# MKW31Z4 register map
Vendor: Freescale Semiconductor, Inc.; Series: Kinetis_W; File version: 1.6
CPU: CM0PLUS r0p0, little endian, no MPU, no FPU, VTOR, 2 interrupt priority bits
Registers are 16-bit, read-write, no defined reset value unless marked. A register's access mark holds for its fields unless they carry their own. Offsets are from the block's base; [hi:lo] are bit positions; {n}, {i} and the like mark numbered series.

## RCM — Reset Control Module
Base 0x4007F000; register names take the prefix RCM_
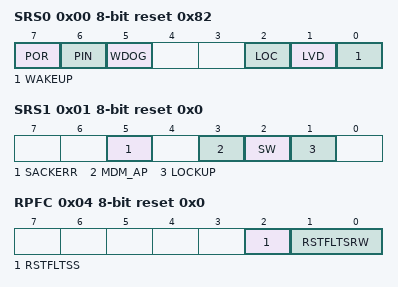
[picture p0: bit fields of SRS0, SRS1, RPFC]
0x00 SRS0 8-bit ro reset 0x82 — System Reset Status Register 0
  [7] POR — Power-On Reset
    0=Reset not caused by POR; 1=Reset caused by POR
  [6] PIN — External Reset Pin
    0=Reset not caused by external reset pin; 1=Reset caused by external reset pin
  [5] WDOG — Watchdog
    0=Reset not caused by watchdog timeout; 1=Reset caused by watchdog timeout
  [2] LOC — Loss-of-Clock Reset
    0=Reset not caused by a loss of external clock; 1=Reset caused by a loss of external clock
  [1] LVD — Low-Voltage Detect Reset
    0=Reset not caused by LVD trip or POR; 1=Reset caused by LVD trip or POR
  [0] WAKEUP — Low Leakage Wakeup Reset
    0=Reset not caused by LLWU module wakeup source; 1=Reset caused by LLWU module wakeup source
0x01 SRS1 8-bit ro reset 0x0 — System Reset Status Register 1
  [5] SACKERR — Stop Mode Acknowledge Error Reset
    0=Reset not caused by peripheral failure to acknowledge attempt to enter stop mode; 1=Reset caused by peripheral failure to acknowledge attempt to enter stop mode
  [3] MDM_AP — MDM-AP System Reset Request
    0=Reset not caused by host debugger system setting of the System Reset Request bit; 1=Reset caused by host debugger system setting of the System Reset Request bit
  [2] SW — Software
    0=Reset not caused by software setting of SYSRESETREQ bit; 1=Reset caused by software setting of SYSRESETREQ bit
  [1] LOCKUP — Core Lockup
    0=Reset not caused by core LOCKUP event; 1=Reset caused by core LOCKUP event
0x04 RPFC 8-bit reset 0x0 — Reset Pin Filter Control register
  [2] RSTFLTSS — Reset Pin Filter Select in Stop Mode
    0=All filtering disabled; 1=LPO clock filter enabled
  [1:0] RSTFLTSRW — Reset Pin Filter Select in Run and Wait Modes
    0=All filtering disabled; 1=Bus clock filter enabled for normal operation; 2=LPO clock filter enabled for normal operation
0x05 RPFW 8-bit reset 0x0 — Reset Pin Filter Width register
  [4:0] RSTFLTSEL — Reset Pin Filter Bus Clock Select
    {v}=Bus clock filter count is {v+1} (v=0..31)

## GPIOA — General Purpose Input/Output
Base 0x400FF000; register names take the prefix GPIOA_
0x00 PDOR 32-bit reset 0x0 — Port Data Output Register
  [31:0] PDO — Port Data Output
    0=Logic level 0 is driven on pin, provided pin is configured for general-purpose output; 1=Logic level 1 is driven on pin, provided pin is configured for general-purpose output
0x04 PSOR 32-bit wo reset 0x0 — Port Set Output Register
  [31:0] PTSO — Port Set Output
    0=Corresponding bit in PDORn does not change; 1=Corresponding bit in PDORn is set to logic 1
0x08 PCOR 32-bit wo reset 0x0 — Port Clear Output Register
  [31:0] PTCO — Port Clear Output
    0=Corresponding bit in PDORn does not change; 1=Corresponding bit in PDORn is cleared to logic 0
0x0C PTOR 32-bit wo reset 0x0 — Port Toggle Output Register
  [31:0] PTTO — Port Toggle Output
    0=Corresponding bit in PDORn does not change; 1=Corresponding bit in PDORn is set to the inverse of its existing logic state
0x10 PDIR 32-bit ro reset 0x0 — Port Data Input Register
  [31:0] PDI — Port Data Input
    0=Pin logic level is logic 0, or is not configured for use by digital function; 1=Pin logic level is logic 1
0x14 PDDR 32-bit reset 0x0 — Port Data Direction Register
  [31:0] PDD — Port Data Direction
    0=Pin is configured as general-purpose input, for the GPIO function; 1=Pin is configured as general-purpose output, for the GPIO function

## GPIOB — General Purpose Input/Output
Base 0x400FF040; register names take the prefix GPIOB_
Registers as GPIOA.

## GPIOC — General Purpose Input/Output
Base 0x400FF080; register names take the prefix GPIOC_
Registers as GPIOA.

## FGPIOA — General Purpose Input/Output
Base 0xF8000000; register names take the prefix FGPIOA_
Registers as GPIOA.

## FGPIOB — General Purpose Input/Output
Base 0xF8000040; register names take the prefix FGPIOB_
Registers as GPIOA.

## FGPIOC — General Purpose Input/Output
Base 0xF8000080; register names take the prefix FGPIOC_
Registers as GPIOA.

## Notices in the file
Redistribution and use in source and binary forms, with or without modification,
are permitted provided that the following conditions are met:
o Redistributions of source code must retain the above copyright notice, this list
of conditions and the following disclaimer.
o Redistributions in binary form must reproduce the above copyright notice, this
list of conditions and the following disclaimer in the documentation and/or
other materials provided with the distribution.
o Neither the name of Freescale Semiconductor, Inc. nor the names of its
contributors may be used to endorse or promote products derived from this
software without specific prior written permission.
THIS SOFTWARE IS PROVIDED BY THE COPYRIGHT HOLDERS AND CONTRIBUTORS "AS IS" AND
ANY EXPRESS OR IMPLIED WARRANTIES, INCLUDING, BUT NOT LIMITED TO, THE IMPLIED
WARRANTIES OF MERCHANTABILITY AND FITNESS FOR A PARTICULAR PURPOSE ARE
DISCLAIMED. IN NO EVENT SHALL THE COPYRIGHT HOLDER OR CONTRIBUTORS BE LIABLE FOR
ANY DIRECT, INDIRECT, INCIDENTAL, SPECIAL, EXEMPLARY, OR CONSEQUENTIAL DAMAGES
(INCLUDING, BUT NOT LIMITED TO, PROCUREMENT OF SUBSTITUTE GOODS OR SERVICES;
LOSS OF USE, DATA, OR PROFITS; OR BUSINESS INTERRUPTION) HOWEVER CAUSED AND ON
ANY THEORY OF LIABILITY, WHETHER IN CONTRACT, STRICT LIABILITY, OR TORT
(INCLUDING NEGLIGENCE OR OTHERWISE) ARISING IN ANY WAY OUT OF THE USE OF THIS
SOFTWARE, EVEN IF ADVISED OF THE POSSIBILITY OF SUCH DAMAGE.
